# nrf9230_enga_radiocore register map
Vendor: Nordic Semiconductor; Series: nRF92; File version: 1
CPU: CM33 r0p4, little endian, MPU, FPU, 3 interrupt priority bits, 480 interrupts, 4 SAU regions
Registers are 32-bit, read-write, reset 0x0 unless marked. A register's access mark holds for its fields unless they carry their own. Offsets are from the block's base; [hi:lo] are bit positions; lines under a group give offsets from that group; 'fields as' and 'values as' point back to an identical list.

## BILS_S — The Built-in Leakage Sensor (BILS) module.
Base 0x5301C000
0x400 CONFIG group — Unspecified
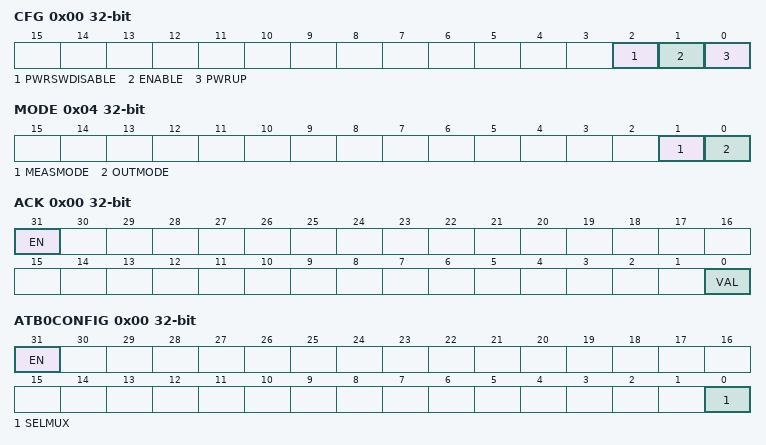
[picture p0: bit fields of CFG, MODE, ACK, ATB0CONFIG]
  0x00 CFG — BILS configuration
    [2] PWRSWDISABLE — Disable power switch.
      0=PwrSwNormalMode (Normal control of the power switch.); 1=PwrSwDisabledMode (Power switch is turned off.)
    [1] ENABLE — BILS enable
      0=BilsDisable (Disable BILS, REQ_SWOFF_AO_0V8 = 0); 1=BilsEnable (Enable BILS, REQ_SWOFF_AO_0V8 is controlled by BILS)
    [0] PWRUP — Power up BILS
      0=PwrOff (BILS is powered down and REQ_SWOFF_AO_0V8=0); 1=PwrOn (BILS is powered up)
  0x04 MODE — Mode selection
    [1] MEASMODE — Measurement mode selection
      0=MeasDisMode (Measure discharge rate); 1=MeasPwMode (Measure power switch chain propagation delay)
    [0] OUTMODE — Output mode selection
      0=Duty50Mode (50:50 duty cycle output selected to FOUT_AO_0V8 pin); 1=CompMode (Comparator output selected to FOUT_AO_0V8 pin)
0x500 OVERRIDE group — Unspecified
  0x00 ACK — Override the ACL_SWOFF_0V8 signal
    [31] EN — Override enable
      0=Disabled (Override disabled); 1=Enabled (Override is enabled)
    [0] VAL — Override value
0x600 DFT group — Unspecified
  0x00 ATB0CONFIG — Analog Test Bus 0 (ATB0) configuration
    [31] EN — Enable the analog test bus
      0=Disabled (Analog test bus is disabled); 1=Enabled (Analog test bus is enabled)
    [0] SELMUX — Select multiplexer for ATB0
      0=None selected; 1=Connect (Voltage on ATB0 used as threshold voltage)
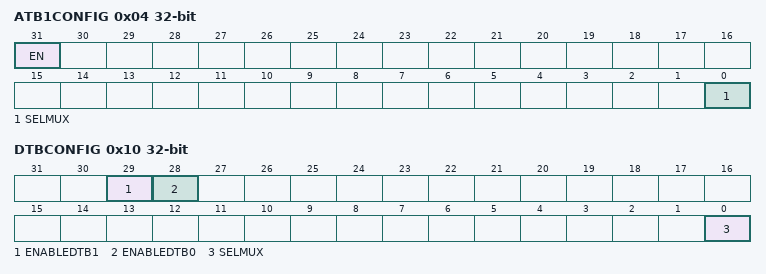
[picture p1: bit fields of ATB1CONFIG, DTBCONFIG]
  0x04 ATB1CONFIG — Analog Test Bus 1 (ATB1) configuration
    [31] EN — Enable the analog test bus
      values as DFT.ATB0CONFIG.EN
    [0] SELMUX — Select multiplexer for ATB1
      0=None selected; 1=ConnectDVDD (ATB1 connected to DVDD_0V8_SW)
  0x10 DTBCONFIG — Digital Test Bus configuration
    [29] ENABLEDTB1 — Enable the digital test bus
      0=Disabled (Digital test bus is disabled); 1=Enabled (Digital test bus is enabled)
    [28] ENABLEDTB0 — Enable the digital test bus
      values as ENABLEDTB1
    [0] SELMUX — Select multiplexer for DTB0
      0=None selected; 1=Connect (FOUT_AO_0V8 is connected to DTB0, REQ_SWOFF_AO_0V8 is connected to DTB1)

## RESETINFO_S — RESETINFO
Base 0x5301E000; alternate view of LRCCONF010_S
0x4A0 RESETREAS group — Unspecified
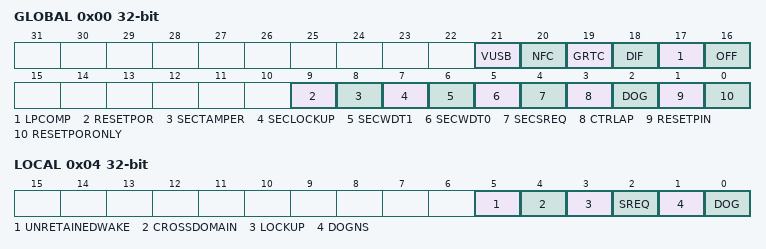
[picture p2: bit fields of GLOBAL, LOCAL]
  0x00 GLOBAL — Global reset reason.
    [all] fields
      0=NotDetected; 1=Detected
    [21] VUSB — Reset after wakeup from System OFF mode due to VBUS rising into valid range.
    [20] NFC — Reset due to wakeup from System OFF mode when wakeup is triggered by NFC field detection in sense mode.
    [19] GRTC — Reset due to wakeup from System OFF mode when wakeup is triggered by GRTC interrupt.
    [18] DIF — Reset due to wakeup from System OFF mode when wakeup is triggered by entering the debug interface mode.
    [17] LPCOMP — Reset due to wakeup from System OFF mode when wakeup is triggered by LPCOMP (Low Power Comparator).
    [16] OFF — Reset due to wakeup from System OFF mode when wakeup is triggered by DETECT signal from GPIO.
    [9] RESETPOR — Reset from power on reset (reset reason other than POR or BOR).
    [8] SECTAMPER — Reset due to secure domain tamper detected
    [7] SECLOCKUP — Reset due to secure domain lockup.
    [6] SECWDT1 — Reset due to the second instance of watchdog timer in secure domain detected.
    [5] SECWDT0 — Reset due to the first instance of watchdog timer in secure domain detected.
    [4] SECSREQ — Reset due to secure domain system reset request.
    [3] CTRLAP — Reset from CTRL-AP detected.
    [2] DOG — Reset from the SysCtrl watchdog timer detected.
    [1] RESETPIN — Reset from pin reset detected.
    [0] RESETPORONLY — Reset from power on reset (reset reason POR or BOR).
  0x04 LOCAL — Local reset reason.
    [5] UNRETAINEDWAKE — Reset due to wake from unretained state.
    [4] CROSSDOMAIN — Reset due to cross domain reset source.
      0=NotDetected; 1=Detected
    [3] LOCKUP — Reset from local CPU lockup detected
      0=NotDetected; 1=Detected
    [2] SREQ — Reset from the local soft reset request detected.
      0=NotDetected; 1=Detected
    [1] DOGNS — Reset from the local non-secure watchdog timer detected
      0=NotDetected; 1=Detected
    [0] DOG — Reset from the local watchdog timer detected
      0=NotDetected; 1=Detected
0x4A8 ERROR group — Unspecified
  0x00 STATUS — Reset error status.
    [3:0] ERRORSTATUS
  0x04 ADDRESS — Reset error address.
    [31:0] ERRORADDRESS
0x4C0 RESTOREVALID — Valid restore image is present in RAM.
  [0] RESTOREVALID
    0=NotPreset (Not present); 1=Present
0x4C4 MASKLOCKUP — Mask CPU lockup signal.
  [0] MASK — Mask lockup signal
    0=NotMask (Do not mask lockup signal); 1=Mask lockup signal

## Notices in the file
Copyright (c) 2010 - 2024, Nordic Semiconductor ASA
All rights reserved.
Redistribution and use in source and binary forms, with or without modification,
are permitted provided that the following conditions are met:
1. Redistributions of source code must retain the above copyright notice, this
list of conditions and the following disclaimer.
2. Redistributions in binary form, except as embedded into a Nordic
Semiconductor ASA integrated circuit in a product or a software update for
such product, must reproduce the above copyright notice, this list of
conditions and the following disclaimer in the documentation and/or other
materials provided with the distribution.
3. Neither the name of Nordic Semiconductor ASA nor the names of its
contributors may be used to endorse or promote products derived from this
software without specific prior written permission.
4. This software, with or without modification, must only be used with a
Nordic Semiconductor ASA integrated circuit.
5. Any software provided in binary form under this license must not be reverse
engineered, decompiled, modified and/or disassembled.
THIS SOFTWARE IS PROVIDED BY NORDIC SEMICONDUCTOR ASA "AS IS" AND ANY EXPRESS
OR IMPLIED WARRANTIES, INCLUDING, BUT NOT LIMITED TO, THE IMPLIED WARRANTIES
OF MERCHANTABILITY, NONINFRINGEMENT, AND FITNESS FOR A PARTICULAR PURPOSE ARE
DISCLAIMED. IN NO EVENT SHALL NORDIC SEMICONDUCTOR ASA OR CONTRIBUTORS BE
LIABLE FOR ANY DIRECT, INDIRECT, INCIDENTAL, SPECIAL, EXEMPLARY, OR
CONSEQUENTIAL DAMAGES (INCLUDING, BUT NOT LIMITED TO, PROCUREMENT OF SUBSTITUTE
GOODS OR SERVICES; LOSS OF USE, DATA, OR PROFITS; OR BUSINESS INTERRUPTION)
HOWEVER CAUSED AND ON ANY THEORY OF LIABILITY, WHETHER IN CONTRACT, STRICT
LIABILITY, OR TORT (INCLUDING NEGLIGENCE OR OTHERWISE) ARISING IN ANY WAY OUT
OF THE USE OF THIS SOFTWARE, EVEN IF ADVISED OF THE POSSIBILITY OF SUCH DAMAGE.
